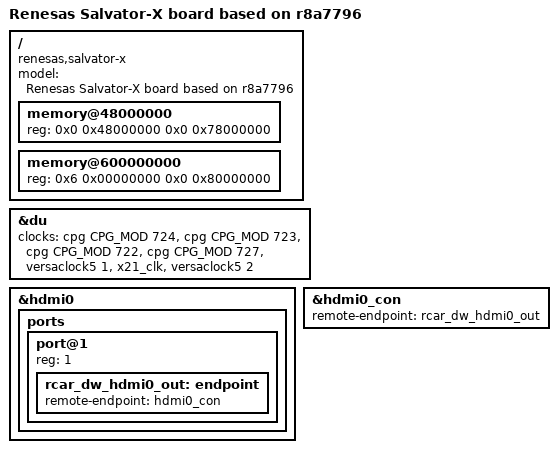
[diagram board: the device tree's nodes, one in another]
/*
 * Device Tree Source for the Salvator-X board with R-Car M3-W
 *
 * Copyright (C) 2016 Renesas Electronics Corp.
 *
 * This file is licensed under the terms of the GNU General Public License
 * version 2.  This program is licensed "as is" without any warranty of any
 * kind, whether express or implied.
 */

/dts-v1/;
#include "r8a7796.dtsi"
#include "salvator-x.dtsi"

/ {
	model = "Renesas Salvator-X board based on r8a7796";
	compatible = "renesas,salvator-x", "renesas,r8a7796";

	memory@48000000 {
		device_type = "memory";
		/* first 128MB is reserved for secure area. */
		reg = <0x0 0x48000000 0x0 0x78000000>;
	};

	memory@600000000 {
		device_type = "memory";
		reg = <0x6 0x00000000 0x0 0x80000000>;
	};
};

&du {
	clocks = <&cpg CPG_MOD 724>,
		 <&cpg CPG_MOD 723>,
		 <&cpg CPG_MOD 722>,
		 <&cpg CPG_MOD 727>,
		 <&versaclock5 1>,
		 <&x21_clk>,
		 <&versaclock5 2>;
	clock-names = "du.0", "du.1", "du.2", "lvds.0",
		      "dclkin.0", "dclkin.1", "dclkin.2";
};

&hdmi0 {
	status = "okay";

	ports {
		port@1 {
			reg = <1>;
			rcar_dw_hdmi0_out: endpoint {
				remote-endpoint = <&hdmi0_con>;
			};
		};
	};
};

&hdmi0_con {
	remote-endpoint = <&rcar_dw_hdmi0_out>;
};
